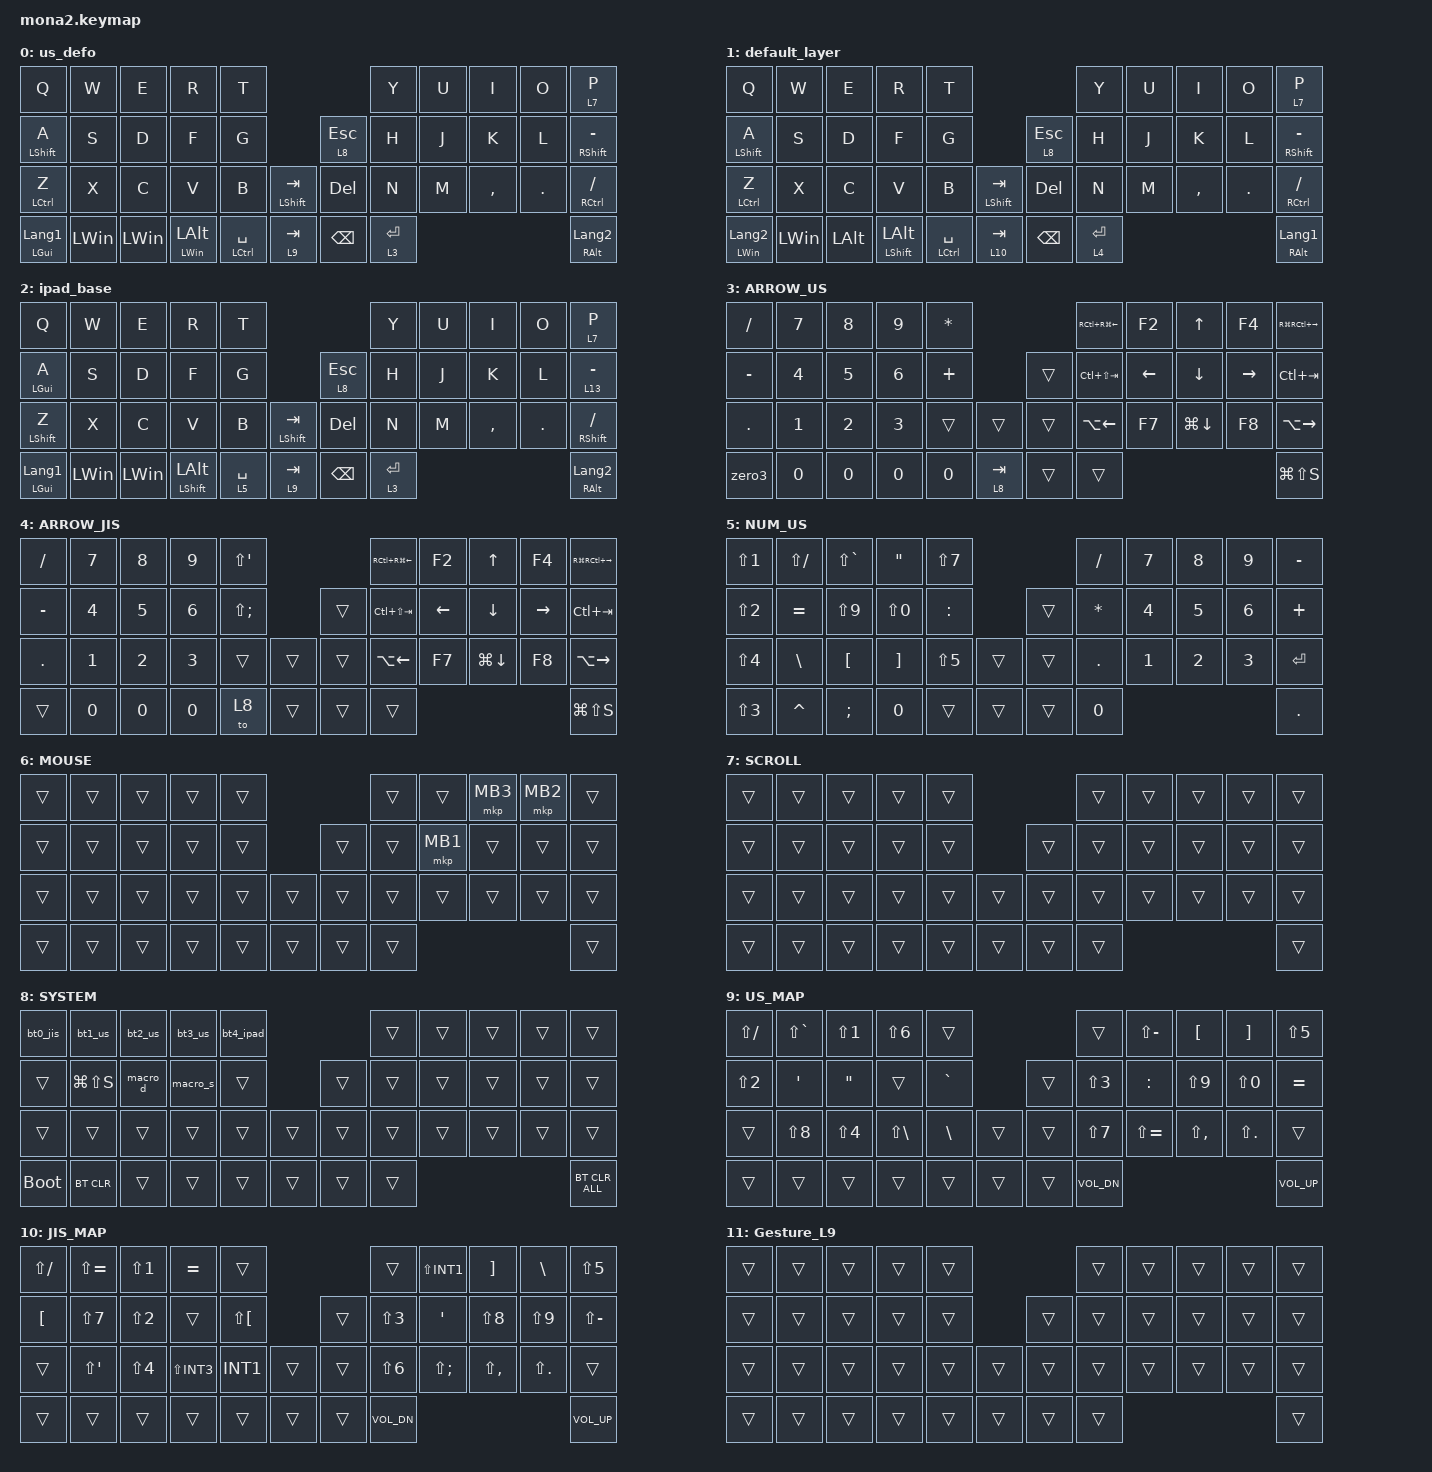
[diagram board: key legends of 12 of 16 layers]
#include <behaviors/rgbled_widget.dtsi>
#include <behaviors.dtsi>
#include <dt-bindings/zmk/bt.h>
#include <dt-bindings/zmk/keys.h>
#include <dt-bindings/zmk/pointing.h>
#include "gesture/gesture_L7.dtsi"
#include "gesture/gesture_L8.dtsi"
#include "gesture/gesture_L9.dtsi"

#define ZMK_POINTING_DEFAULT_SCRL_VAL 100

/* --- レイヤー番号の定義 ---
 * LY_プレフィックスでdevicetreeのブロック名との衝突を回避
 */

#define LY_DEF       0
#define LY_US_D      1
#define LY_IPAD      2
#define LY_ARR_US    3
#define LY_ARR_JIS   4
#define LY_NUM_US    5
#define LY_MOUSE     6
#define LY_SCR       7
#define LY_SYS       8
#define LY_US_M      9
#define LY_JIS_M     10
#define LY_GEST_L9   11
#define LY_NUMJIS    12
#define LY_IPAD_ACT  13

&mt {
    flavor = "balanced";
    quick-tap-ms = <0>;
};

&lt {
    quick-tap-ms = <200>;
    flavor = "balanced";
};

&sl { release-after-ms = <250>; };

/ {
    combos {
        compatible = "zmk,combos";

        Gesture_L8 {
            bindings = <&kp DELETE>;
            key-positions = <9 8>;
        };

        combo_esc {
            bindings = <&kp ESCAPE>;
            key-positions = <0 1>;
        };

        combo_tab {
            bindings = <&kp TAB>;
            key-positions = <11 12>;
        };

        combo_minus {
            bindings = <&kp MINUS>;
            key-positions = <31 32>;
        };

        combo_del {
            bindings = <&kp DELETE>;
            key-positions = <8 9>;
        };

        /* J+K -> LANGUAGE_1 / K+L -> LANGUAGE_2
         * 土台レイヤー(0=JIS, 1=US, 2=iPad)でのみ有効(MOUSEなど上のレイヤーでは無効) */

        combo_lang1 {
            bindings = <&kp LANGUAGE_1>;
            key-positions = <17 18>;
        };

        combo_lang2 {
            bindings = <&kp LANGUAGE_2>;
            key-positions = <18 19>;
        };
    };

    macros {
        to_layer_0: to_layer_0 {
            compatible = "zmk,behavior-macro-one-param";
            #binding-cells = <1>;
            bindings = <&to 2 &macro_param_1to1 &kp MACRO_PLACEHOLDER>;
            label = "TO_LAYER_0";
        };

        mul_mark: x_sign_win {
            compatible = "zmk,behavior-macro";
            #binding-cells = <0>;
            wait-ms = <10>;
            tap-ms = <10>;
            bindings =
                <&macro_press>,
                <&kp LALT>,
                <&macro_tap>,
                <&kp KP_N0 &kp KP_N2 &kp KP_N1 &kp KP_N5>,
                <&macro_release>,
                <&kp LALT>;
        };

        div_mark: div_mark {
            compatible = "zmk,behavior-macro";
            label = "DIV_MARK";
            #binding-cells = <0>;
            wait-ms = <10>;
            tap-ms = <10>;
            bindings =
                <&macro_press>,
                <&kp LALT>,
                <&macro_tap>,
                <&kp KP_N0 &kp KP_N2 &kp KP_N4 &kp KP_N7>,
                <&macro_release>,
                <&kp LALT>;
        };

        to_layer_0_mkp: to_layer_0_mkp {
            compatible = "zmk,behavior-macro-one-param";
            #binding-cells = <1>;
            bindings = <&to 2 &macro_param_1to1 &mkp MACRO_PLACEHOLDER>;
            label = "TO_LAYER_0_MKP";
        };

        macro_s: macro_s {
            compatible = "zmk,behavior-macro";
            #binding-cells = <0>;
            wait-ms = <30>;
            tap-ms = <30>;
            bindings = <&kp H &kp O &kp N &kp N &kp A &kp D &kp A &kp I>;
            label = "MACRO_S";
        };

        macro_d: macro_d {
            compatible = "zmk,behavior-macro";
            #binding-cells = <0>;
            wait-ms = <30>;
            tap-ms = <30>;
            bindings = <&kp LS(A) &kp N2 &kp N9 &kp N5 &kp X &kp P>;
            label = "MACRO_D";
        };

        bt0_jis: bt0_jis {
            compatible = "zmk,behavior-macro";
            #binding-cells = <0>;
            wait-ms = <10>;
            tap-ms = <10>;
            bindings = <&bt BT_SEL 0 &to 0>;
            label = "BT0_JIS";
        };

        bt1_us: bt1_us {
            compatible = "zmk,behavior-macro";
            #binding-cells = <0>;
            wait-ms = <10>;
            tap-ms = <10>;
            bindings = <&bt BT_SEL 1 &to 0>;
            label = "BT1_US";
        };

        bt2_us: bt2_us {
            compatible = "zmk,behavior-macro";
            #binding-cells = <0>;
            wait-ms = <10>;
            tap-ms = <10>;
            bindings = <&bt BT_SEL 2 &to 1>;
            label = "BT2_US";
        };

        bt3_us: bt3_us {
            compatible = "zmk,behavior-macro";
            #binding-cells = <0>;
            wait-ms = <10>;
            tap-ms = <10>;
            bindings = <&bt BT_SEL 3 &to 0>;
            label = "BT3_US";
        };

        bt4_ipad: bt4_ipad {
            compatible = "zmk,behavior-macro";
            #binding-cells = <0>;
            wait-ms = <10>;
            tap-ms = <10>;
            bindings = <&bt BT_SEL 4 &to 2>;
            label = "BT4_IPAD";
        };

        ipad_home: ipad_home {
            compatible = "zmk,behavior-macro";
            #binding-cells = <0>;
            wait-ms = <30>;
            tap-ms = <30>;
            bindings =
                <&macro_press>,
                <&kp GLOBE>,
                <&macro_tap>,
                <&kp H>,
                <&macro_release>,
                <&kp GLOBE>;

            label = "IPAD_HOME";
        };

        ipad_full: ipad_full {
            compatible = "zmk,behavior-macro";
            #binding-cells = <0>;
            wait-ms = <30>;
            tap-ms = <30>;
            bindings =
                <&macro_press>,
                <&kp GLOBE>,
                <&macro_tap>,
                <&kp F>,
                <&macro_release>,
                <&kp GLOBE>;

            label = "IPAD_FULL";
        };

        ipad_recent: ipad_recent {
            compatible = "zmk,behavior-macro";
            #binding-cells = <0>;
            wait-ms = <30>;
            tap-ms = <30>;
            bindings =
                <&macro_press>,
                <&kp GLOBE>,
                <&macro_tap>,
                <&kp UP>,
                <&macro_release>,
                <&kp GLOBE>;

            label = "IPAD_RECENT";
        };

        ipad_dock: ipad_dock {
            compatible = "zmk,behavior-macro";
            #binding-cells = <0>;
            wait-ms = <30>;
            tap-ms = <30>;
            bindings =
                <&macro_press>,
                <&kp GLOBE>,
                <&macro_tap>,
                <&kp A>,
                <&macro_release>,
                <&kp GLOBE>;

            label = "IPAD_DOCK";
        };

        ipad_applib: ipad_applib {
            compatible = "zmk,behavior-macro";
            #binding-cells = <0>;
            wait-ms = <30>;
            tap-ms = <30>;
            bindings =
                <&macro_press>,
                <&kp GLOBE &kp LSHIFT>,
                <&macro_tap>,
                <&kp A>,
                <&macro_release>,
                <&kp GLOBE &kp LSHIFT>;

            label = "IPAD_APPLIB";
        };

        ipad_left: ipad_left {
            compatible = "zmk,behavior-macro";
            #binding-cells = <0>;
            wait-ms = <30>;
            tap-ms = <30>;
            bindings =
                <&macro_press>,
                <&kp LCTRL &kp GLOBE>,
                <&macro_tap>,
                <&kp LEFT>,
                <&macro_release>,
                <&kp LCTRL &kp GLOBE>;

            label = "IPAD_LEFT";
        };

        ipad_right: ipad_right {
            compatible = "zmk,behavior-macro";
            #binding-cells = <0>;
            wait-ms = <30>;
            tap-ms = <30>;
            bindings =
                <&macro_press>,
                <&kp LCTRL &kp GLOBE>,
                <&macro_tap>,
                <&kp RIGHT>,
                <&macro_release>,
                <&kp LCTRL &kp GLOBE>;

            label = "IPAD_RIGHT";
        };
    };

    behaviors {
        lt_to_layer_0: lt_to_layer_0 {
            compatible = "zmk,behavior-hold-tap";
            label = "LAYER_TAP_TO_0";
            #binding-cells = <2>;
            tapping-term-ms = <200>;
            bindings = <&mo>, <&to_layer_0>;
        };

        scroll_up_down: mouse_wheel_up_down {
            compatible = "zmk,behavior-sensor-rotate";
            #sensor-binding-cells = <0>;
            tap-ms = <40>;
            bindings = <&msc SCRL_DOWN>, <&msc SCRL_UP>;
        };

        scroll_right_left: mouse_wheel_right_left {
            compatible = "zmk,behavior-sensor-rotate";
            #sensor-binding-cells = <0>;
            tap-ms = <40>;
            bindings = <&msc SCRL_LEFT>, <&msc SCRL_RIGHT>;
        };

        page_encoder: page_encoder {
            compatible = "zmk,behavior-sensor-rotate";
            #sensor-binding-cells = <0>;
            bindings = <&kp LC(PAGE_DOWN)>, <&kp LC(PAGE_UP)>;
        };

        fusion_orbit: fusion_orbit {
            compatible = "zmk,behavior-macro";
            #binding-cells = <0>;
            bindings =
                <&macro_press>,
                <&kp LSHIFT &mkp MB3>,
                <&macro_pause_for_release>,
                <&macro_release>,
                <&kp LSHIFT &mkp MB3>;

            label = "FUSION_ORBIT";
        };

        pass: new_macro {
            compatible = "zmk,behavior-macro";
            #binding-cells = <0>;
            bindings = <&kp RIGHT_PARENTHESIS &kp H &kp H &kp Q &kp W &kp N9 &kp H>;
            label = "NEW_MACRO";
        };

        admini: admini {
            compatible = "zmk,behavior-macro";
            #binding-cells = <0>;
            bindings = <&kp A &kp D &kp M &kp I &kp N &kp I &kp S &kp T &kp R &kp A &kp T &kp O &kp R>;
            label = "ADMINI";
        };

        zero3: zerozerozero {
            compatible = "zmk,behavior-macro";
            #binding-cells = <0>;
            bindings = <&kp N0 &kp NUMBER_0 &kp N0>;
            label = "ZEROZEROZERO";
        };
    };

    keymap {
        compatible = "zmk,keymap";

        /* [0] DEFAULT (JIS OS用) */

        us_defo {
            bindings = <
&kp Q                    &kp W         &kp E         &kp R                  &kp T                                                        &kp Y        &kp U  &kp I      &kp O    &lt 7 P
&mt LEFT_SHIFT A         &kp S         &kp D         &kp F                  &kp G                                         &lt 8 ESC      &kp H        &kp J  &kp K      &kp L    &mt RIGHT_SHIFT MINUS
&mt LEFT_CONTROL Z       &kp X         &kp C         &kp V                  &kp B                   &mt LEFT_SHIFT TAB    &kp DEL        &kp N        &kp M  &kp COMMA  &kp DOT  &mt RIGHT_CONTROL SLASH
&mt LEFT_GUI LANGUAGE_1  &kp LEFT_WIN  &kp LEFT_WIN  &mt LEFT_WIN LEFT_ALT  &mt LEFT_CONTROL SPACE  &lt 9 TAB             &kp BACKSPACE  &lt 3 ENTER                             &mt RIGHT_ALT LANGUAGE_2
            >;

            sensor-bindings = <&scroll_up_down>;
        };

        default_layer {
            bindings = <
&kp Q                    &kp W         &kp E         &kp R                    &kp T                                                        &kp Y        &kp U  &kp I      &kp O    &lt 7 P
&mt LEFT_SHIFT A         &kp S         &kp D         &kp F                    &kp G                                         &lt 8 ESC      &kp H        &kp J  &kp K      &kp L    &mt RIGHT_SHIFT MINUS
&mt LEFT_CONTROL Z       &kp X         &kp C         &kp V                    &kp B                   &mt LEFT_SHIFT TAB    &kp DELETE     &kp N        &kp M  &kp COMMA  &kp DOT  &mt RIGHT_CONTROL SLASH
&mt LEFT_WIN LANGUAGE_2  &kp LEFT_WIN  &kp LEFT_ALT  &mt LEFT_SHIFT LEFT_ALT  &mt LEFT_CONTROL SPACE  &lt 10 TAB            &kp BACKSPACE  &lt 4 ENTER                             &mt RIGHT_ALT LANGUAGE_1
            >;

            sensor-bindings = <&scroll_up_down>;
        };

        ipad_base {
            bindings = <
&kp Q                    &kp W         &kp E         &kp R                    &kp T                                             &kp Y        &kp U  &kp I      &kp O    &lt 7 P
&mt LEFT_GUI A           &kp S         &kp D         &kp F                    &kp G                              &lt 8 ESC      &kp H        &kp J  &kp K      &kp L    &lt 13 MINUS
&mt LEFT_SHIFT Z         &kp X         &kp C         &kp V                    &kp B        &mt LEFT_SHIFT TAB    &kp DEL        &kp N        &kp M  &kp COMMA  &kp DOT  &mt RIGHT_SHIFT SLASH
&mt LEFT_GUI LANGUAGE_1  &kp LEFT_WIN  &kp LEFT_WIN  &mt LEFT_SHIFT LEFT_ALT  &lt 5 SPACE  &lt 9 TAB             &kp BACKSPACE  &lt 3 ENTER                             &mt RIGHT_ALT LANGUAGE_2
            >;

            sensor-bindings = <&scroll_up_down>;
        };

        ARROW_US {
            bindings = <
&kp SLASH  &kp NUMBER_7  &kp NUMBER_8  &kp NUMBER_9  &kp ASTERISK                       &kp RC(RG(LEFT))  &kp F2    &kp UP        &kp F4     &kp RG(RC(RIGHT))
&kp MINUS  &kp NUMBER_4  &kp NUMBER_5  &kp NUMBER_6  &kp PLUS                   &trans  &kp LC(LS(TAB))   &kp LEFT  &kp DOWN      &kp RIGHT  &kp LC(TAB)
&kp DOT    &kp NUMBER_1  &kp NUMBER_2  &kp NUMBER_3  &trans        &trans       &trans  &kp LA(LEFT)      &kp F7    &kp LG(DOWN)  &kp F8     &kp LA(RIGHT)
&zero3     &kp NUMBER_0  &kp N0        &kp NUMBER_0  &kp N0        &lt 8 TAB    &trans  &trans                                               &kp LG(LS(S))
            >;

            sensor-bindings = <&inc_dec_kp K_VOLUME_UP K_VOLUME_DOWN>;
        };

        ARROW_JIS {
            bindings = <
&kp SLASH  &kp NUMBER_7  &kp NUMBER_8  &kp NUMBER_9  &kp LS(SQT)                     &kp RC(RG(LEFT))  &kp F2    &kp UP        &kp F4     &kp RG(RC(RIGHT))
&kp MINUS  &kp NUMBER_4  &kp NUMBER_5  &kp NUMBER_6  &kp LS(SEMI)            &trans  &kp LC(LS(TAB))   &kp LEFT  &kp DOWN      &kp RIGHT  &kp LC(TAB)
&kp DOT    &kp NUMBER_1  &kp NUMBER_2  &kp NUMBER_3  &trans        &trans    &trans  &kp LA(LEFT)      &kp F7    &kp LG(DOWN)  &kp F8     &kp LA(RIGHT)
&trans     &kp NUMBER_0  &kp NUMBER_0  &kp NUMBER_0  &to 8         &trans    &trans  &trans                                               &kp LG(LS(S))
            >;

            sensor-bindings = <&scroll_up_down>;
        };

        NUM_US {
            bindings = <
&kp LS(N1)  &kp LS(SLASH)  &kp LS(GRAVE)  &kp DQT       &kp LS(N7)                    &kp SLASH     &kp NUMBER_7  &kp NUMBER_8  &kp NUMBER_9  &kp MINUS
&kp LS(N2)  &kp EQUAL      &kp LS(N9)     &kp LS(N0)    &kp COLON             &trans  &kp ASTERISK  &kp NUMBER_4  &kp NUMBER_5  &kp NUMBER_6  &kp PLUS
&kp LS(N4)  &kp BSLH       &kp LBKT       &kp RBKT      &kp LS(N5)  &trans    &trans  &kp PERIOD    &kp NUMBER_1  &kp NUMBER_2  &kp NUMBER_3  &kp ENTER
&kp LS(N3)  &kp CARET      &kp SEMICOLON  &kp NUMBER_0  &trans      &trans    &trans  &kp N0                                                  &kp PERIOD
            >;

            sensor-bindings = <&page_encoder>;
        };

        MOUSE {
            bindings = <
&trans  &trans  &trans  &trans  &trans                    &trans  &trans    &mkp MB3  &mkp MB2  &trans
&trans  &trans  &trans  &trans  &trans            &trans  &trans  &mkp MB1  &trans    &trans    &trans
&trans  &trans  &trans  &trans  &trans  &trans    &trans  &trans  &trans    &trans    &trans    &trans
&trans  &trans  &trans  &trans  &trans  &trans    &trans  &trans                                &trans
            >;

            sensor-bindings = <&scroll_up_down>;
        };

        SCROLL {
            bindings = <
&trans  &trans  &trans  &trans  &trans                    &trans  &trans  &trans  &trans  &trans
&trans  &trans  &trans  &trans  &trans            &trans  &trans  &trans  &trans  &trans  &trans
&trans  &trans  &trans  &trans  &trans  &trans    &trans  &trans  &trans  &trans  &trans  &trans
&trans  &trans  &trans  &trans  &trans  &trans    &trans  &trans                          &trans
            >;
        };

        SYSTEM {
            bindings = <
&bt0_jis     &bt1_us        &bt2_us   &bt3_us   &bt4_ipad                    &trans  &trans  &trans  &trans  &trans
&trans       &kp LG(LS(S))  &macro_d  &macro_s  &trans               &trans  &trans  &trans  &trans  &trans  &trans
&trans       &trans         &trans    &trans    &trans     &trans    &trans  &trans  &trans  &trans  &trans  &trans
&bootloader  &bt BT_CLR     &trans    &trans    &trans     &trans    &trans  &trans                          &bt BT_CLR_ALL
            >;
        };

        US_MAP {
            bindings = <
&kp LS(SLASH)  &kp LS(GRAVE)  &kp LS(N1)  &kp LS(N6)    &trans                       &trans        &kp LS(MINUS)  &kp LBKT       &kp RBKT     &kp LS(N5)
&kp LS(N2)     &kp SQT        &kp DQT     &trans        &kp GRAVE            &trans  &kp LS(N3)    &kp COLON      &kp LS(N9)     &kp LS(N0)   &kp EQUAL
&trans         &kp LS(N8)     &kp LS(N4)  &kp LS(BSLH)  &kp BSLH   &trans    &trans  &kp LS(N7)    &kp LS(EQUAL)  &kp LS(COMMA)  &kp LS(DOT)  &trans
&trans         &trans         &trans      &trans        &trans     &trans    &trans  &kp C_VOL_DN                                             &kp C_VOL_UP
            >;
        };

        JIS_MAP {
            bindings = <
&kp LS(SLASH)  &kp LS(EQUAL)  &kp LS(N1)  &kp EQUAL     &trans                          &trans        &kp LS(INT1)  &kp RBKT       &kp BSLH     &kp LS(N5)
&kp LBKT       &kp LS(N7)     &kp LS(N2)  &trans        &kp LS(LBKT)            &trans  &kp LS(N3)    &kp SQT       &kp LS(N8)     &kp LS(N9)   &kp LS(MINUS)
&trans         &kp LS(SQT)    &kp LS(N4)  &kp LS(INT3)  &kp INT1      &trans    &trans  &kp LS(N6)    &kp LS(SEMI)  &kp LS(COMMA)  &kp LS(DOT)  &trans
&trans         &trans         &trans      &trans        &trans        &trans    &trans  &kp C_VOL_DN                                            &kp C_VOL_UP
            >;
        };

        Gesture_L9 {
            bindings = <
&trans  &trans  &trans  &trans  &trans                    &trans  &trans  &trans  &trans  &trans
&trans  &trans  &trans  &trans  &trans            &trans  &trans  &trans  &trans  &trans  &trans
&trans  &trans  &trans  &trans  &trans  &trans    &trans  &trans  &trans  &trans  &trans  &trans
&trans  &trans  &trans  &trans  &trans  &trans    &trans  &trans                          &trans
            >;
        };

        NUMJIS {
            bindings = <
&kp LS(N1)  &kp LS(SLASH)  &kp LS(EQUAL)  &kp LS(N2)    &kp LS(N6)                      &kp SLASH     &kp NUMBER_7  &kp NUMBER_8  &kp NUMBER_9  &kp MINUS
&kp LBKT    &kp LS(MINUS)  &kp LS(N8)     &kp LS(N9)    &kp SQT                 &trans  &kp RS(SQT)   &kp NUMBER_4  &kp NUMBER_5  &kp NUMBER_6  &kp RS(SEMICOLON)
&kp LS(N4)  &kp INT1       &kp RBKT       &kp BSLH      &kp LS(N5)  &kp SEMI    &trans  &kp PERIOD    &kp NUMBER_1  &kp NUMBER_2  &kp NUMBER_3  &kp ENTER
&kp LS(N3)  &trans         &trans         &kp NUMBER_0  &trans      &trans      &trans  &kp NUMBER_0                                            &kp PERIOD
            >;

            sensor-bindings = <&page_encoder>;
        };

        ipad_act {
            bindings = <
&trans  &trans  &trans  &trans  &trans                    &kp LG(TAB)    &ipad_recent  &ipad_full    &ipad_dock   &trans
&trans  &trans  &trans  &trans  &trans            &trans  &ipad_home     &ipad_left    &kp LG(M)     &ipad_right  &trans
&trans  &trans  &trans  &trans  &trans  &trans    &trans  &kp LG(SPACE)  &trans        &ipad_applib  &kp LG(W)    &trans
&trans  &trans  &trans  &trans  &trans  &trans    &trans  &trans                                                  &trans
            >;

            sensor-bindings = <&scroll_up_down>;
        };

        /* [14] NUM_US_OLD / [15] NUMJIS_OLD: 数字+記号を一緒にする前の数字レイヤー(復元) */

        num_us_old {
            bindings = <
&kp PAGE_UP   &kp F2    &kp UP_ARROW  &kp F4        &kp MINUS                       &kp SLASH     &kp NUMBER_7  &kp NUMBER_8  &kp NUMBER_9  &kp MINUS
&trans        &kp LEFT  &kp DOWN      &kp RIGHT     &kp LS(SEMI)            &trans  &kp ASTERISK  &kp NUMBER_4  &kp NUMBER_5  &kp NUMBER_6  &kp PLUS
&kp NUMBER_0  &kp F7    &kp F8        &kp F11       &kp NUMBER_0  &trans    &trans  &kp PERIOD    &kp NUMBER_1  &kp NUMBER_2  &kp NUMBER_3  &kp ENTER
&trans        &trans    &trans        &kp NUMBER_0  &trans        &trans    &trans  &kp N0                                                  &kp PERIOD
            >;

            sensor-bindings = <&page_encoder>;
        };

        numjis_old {
            bindings = <
&kp PAGE_UP   &kp F2    &kp UP_ARROW  &kp F4        &kp MINUS                       &kp SLASH     &kp NUMBER_7  &kp NUMBER_8  &kp NUMBER_9  &kp MINUS
&trans        &kp LEFT  &kp DOWN      &kp RIGHT     &kp LS(SEMI)            &trans  &kp RS(SQT)   &kp NUMBER_4  &kp NUMBER_5  &kp NUMBER_6  &kp RS(SEMICOLON)
&kp NUMBER_0  &kp F7    &kp F8        &kp F11       &trans        &trans    &trans  &kp PERIOD    &kp NUMBER_1  &kp NUMBER_2  &kp NUMBER_3  &kp ENTER
&trans        &trans    &trans        &kp NUMBER_0  &trans        &trans    &trans  &kp NUMBER_0                                            &kp PERIOD
            >;

            sensor-bindings = <&page_encoder>;
        };
    };
};
